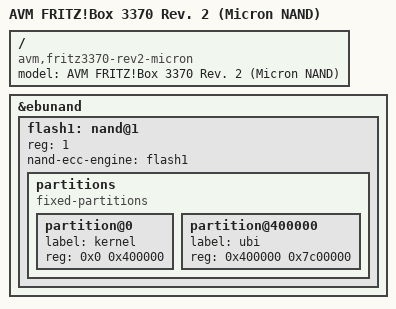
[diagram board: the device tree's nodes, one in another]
#include "vr9_avm_fritz3370-rev2.dtsi"

/ {
	compatible = "avm,fritz3370-rev2-micron", "avm,fritz3370-rev2", "lantiq,xway", "lantiq,vr9";
	model = "AVM FRITZ!Box 3370 Rev. 2 (Micron NAND)";
};

&ebunand {
	status = "okay";

	flash1: nand@1 {
		reg = <1>;

		nand-ecc-engine = <&flash1>;

		partitions {
			compatible = "fixed-partitions";
			#address-cells = <1>;
			#size-cells = <1>;

			partition@0 {
				label = "kernel";
				reg = <0x0 0x400000>;
			};

			partition@400000 {
				label = "ubi";
				reg = <0x400000 0x7c00000>;
			};
		};
	};
};
